# PIC18F45K22 register map
Vendor: Microchip
Registers are 8-bit, read-write, no defined reset value unless marked. A register's access mark holds for its fields unless they carry their own. Addresses are absolute, and some are shared; only a register's first bit layout is shown; [hi:lo] are bit positions; <NAME> marks a mode.

## CONFIG — Configuration words, addresses in ProgramSpace
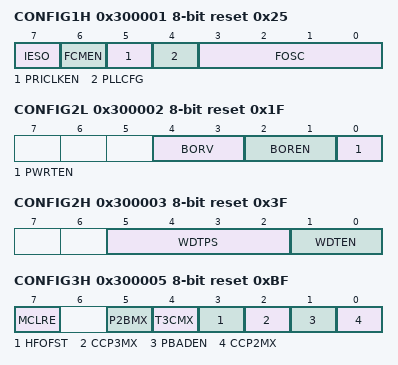
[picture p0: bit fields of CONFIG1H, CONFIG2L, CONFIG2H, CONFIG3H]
0x300001 CONFIG1H reset 0x25
  [7] IESO — Internal/External Oscillator Switchover bit
    0=OFF (Oscillator Switchover mode disabled); 1=ON (Oscillator Switchover mode enabled)
  [6] FCMEN — Fail-Safe Clock Monitor Enable bit
    0=OFF (Fail-Safe Clock Monitor disabled); 1=ON (Fail-Safe Clock Monitor enabled)
  [5] PRICLKEN — Primary clock enable bit
    0=OFF (Primary clock can be disabled by software); 1=ON (Primary clock is always enabled)
  [4] PLLCFG — 4X PLL Enable
    0=OFF (Oscillator used directly); 1=ON (Oscillator multiplied by 4)
  [3:0] FOSC — Oscillator Selection bits
    0b111x=RC (111X External RC oscillator, CLKOUT function on RA6); 13=ECLPIO6 (EC oscillator (low power, <500 kHz)); 12=ECLP (EC oscillator, CLKOUT function on OSC2 (low power, <500 kHz)); 11=ECMPIO6 (EC oscillator (medium power, 500 kHz-16 MHz)); 10=ECMP (EC oscillator, CLKOUT function on OSC2 (medium power, 500 kHz-16 MHz)); 9=INTIO7 (Internal oscillator block, CLKOUT function on OSC2); 8=INTIO67 (Internal oscillator block); 7=RCIO6 (External RC oscillator); 6=RC (External RC oscillator, CLKOUT function on OSC2); 5=ECHPIO6 (EC oscillator (high power, >16 MHz)); 4=ECHP (EC oscillator, CLKOUT function on OSC2 (high power, >16 MHz)); 3=HSMP (HS oscillator (medium power 4-16 MHz)); 2=HSHP (HS oscillator (high power > 16 MHz)); 1=XT (XT oscillator); 0=LP (LP oscillator)
0x300002 CONFIG2L reset 0x1F
  [4:3] BORV — Brown Out Reset Voltage bits
    3=VBOR set to 1.90 V nominal; 2=VBOR set to 2.20 V nominal; 1=VBOR set to 2.50 V nominal; 0=VBOR set to 2.85 V nominal
  [2:1] BOREN — Brown-out Reset Enable bits
    3=SBORDIS (Brown-out Reset enabled in hardware only (SBOREN is disabled)); 2=NOSLP (Brown-out Reset enabled in hardware only and disabled in Sleep mode (SBOREN is disabled)); 1=ON (Brown-out Reset enabled and controlled by software (SBOREN is enabled)); 0=OFF (Brown-out Reset disabled in hardware and software)
  [0] PWRTEN — Power-up Timer Enable bit
    1=OFF (Power up timer disabled); 0=ON (Power up timer enabled)
0x300003 CONFIG2H reset 0x3F
  [5:2] WDTPS — Watchdog Timer Postscale Select bits
    15=1:32768; 14=1:16384; 13=1:8192; 12=1:4096; 11=1:2048; 10=1:1024; 9=1:512; 8=1:256; 7=1:128; 6=1:64; 5=1:32; 4=1:16; 3=1:8; 2=1:4; 1=1:2; 0=1:1
  [1:0] WDTEN — Watchdog Timer Enable bits
    3=ON (WDT is always enabled. SWDTEN bit has no effect); 2=SWON (WDT is controlled by SWDTEN bit of the WDTCON register); 1=NOSLP (WDT is disabled in sleep, otherwise enabled. SWDTEN bit has no effect); 0=OFF (Watch dog timer is always disabled. SWDTEN has no effect.)
0x300005 CONFIG3H reset 0xBF
  [7] MCLRE — MCLR Pin Enable bit
    1=EXTMCLR (MCLR pin enabled, RE3 input pin disabled); 0=INTMCLR (RE3 input pin enabled; MCLR disabled)
  [5] P2BMX — ECCP2 B output mux bit
    1=PORTD2 (P2B is on RD2); 0=PORTC0 (P2B is on RC0)
  [4] T3CMX — Timer3 Clock input mux bit
    1=PORTC0 (T3CKI is on RC0); 0=PORTB5 (T3CKI is on RB5)
  [3] HFOFST — HFINTOSC Fast Start-up
    1=ON (HFINTOSC output and ready status are not delayed by the oscillator stable status); 0=OFF (HFINTOSC output and ready status are delayed by the oscillator stable status)
  [2] CCP3MX — P3A/CCP3 Mux bit
    1=PORTB5 (P3A/CCP3 input/output is multiplexed with RB5); 0=PORTE0 (P3A/CCP3 input/output is mulitplexed with RE0)
  [1] PBADEN — PORTB A/D Enable bit
    1=ON (PORTB<5:0> pins are configured as analog input channels on Reset); 0=OFF (PORTB<5:0> pins are configured as digital I/O on Reset)
  [0] CCP2MX — CCP2 MUX bit
    1=PORTC1 (CCP2 input/output is multiplexed with RC1); 0=PORTB3 (CCP2 input/output is multiplexed with RB3)
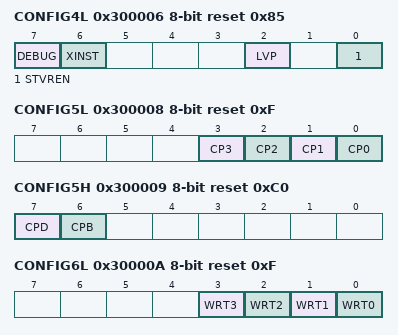
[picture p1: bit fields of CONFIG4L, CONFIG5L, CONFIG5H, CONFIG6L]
0x300006 CONFIG4L reset 0x85
  [7] DEBUG — Background Debug
    1=OFF (Disabled); 0=ON (Enabled)
  [6] XINST — Extended Instruction Set Enable bit
    1=ON (Instruction set extension and Indexed Addressing mode enabled); 0=OFF (Instruction set extension and Indexed Addressing mode disabled (Legacy mode))
  [2] LVP — Single-Supply ICSP Enable bit
    1=ON (Single-Supply ICSP enabled if MCLRE is also 1); 0=OFF (Single-Supply ICSP disabled)
  [0] STVREN — Stack Full/Underflow Reset Enable bit
    1=ON (Stack full/underflow will cause Reset); 0=OFF (Stack full/underflow will not cause Reset)
0x300008 CONFIG5L reset 0xF
  [3] CP3 — Code Protection Block 3
    1=OFF (Block 3 (006000-007FFFh) not code-protected); 0=ON (Block 3 (006000-007FFFh) code-protected)
  [2] CP2 — Code Protection Block 2
    1=OFF (Block 2 (004000-005FFFh) not code-protected); 0=ON (Block 2 (004000-005FFFh) code-protected)
  [1] CP1 — Code Protection Block 1
    1=OFF (Block 1 (002000-003FFFh) not code-protected); 0=ON (Block 1 (002000-003FFFh) code-protected)
  [0] CP0 — Code Protection Block 0
    1=OFF (Block 0 (000800-001FFFh) not code-protected); 0=ON (Block 0 (000800-001FFFh) code-protected)
0x300009 CONFIG5H reset 0xC0
  [7] CPD — Data EEPROM Code Protection bit
    1=OFF (Data EEPROM not code-protected); 0=ON (Data EEPROM code-protected)
  [6] CPB — Boot Block Code Protection bit
    1=OFF (Boot block (000000-0007FFh) not code-protected); 0=ON (Boot block (000000-0007FFh) code-protected)
0x30000A CONFIG6L reset 0xF
  [3] WRT3 — Write Protection Block 3
    1=OFF (Block 3 (006000-007FFFh) not write-protected); 0=ON (Block 3 (006000-007FFFh) write-protected)
  [2] WRT2 — Write Protection Block 2
    1=OFF (Block 2 (004000-005FFFh) not write-protected); 0=ON (Block 2 (004000-005FFFh) write-protected)
  [1] WRT1 — Write Protection Block 1
    1=OFF (Block 1 (002000-003FFFh) not write-protected); 0=ON (Block 1 (002000-003FFFh) write-protected)
  [0] WRT0 — Write Protection Block 0
    1=OFF (Block 0 (000800-001FFFh) not write-protected); 0=ON (Block 0 (000800-001FFFh) write-protected)
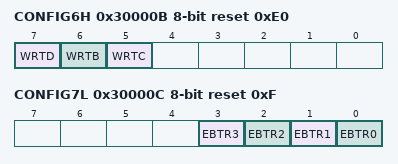
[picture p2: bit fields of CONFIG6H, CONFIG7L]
0x30000B CONFIG6H reset 0xE0
  [7] WRTD — Data EEPROM Write Protection bit
    1=OFF (Data EEPROM not write-protected); 0=ON (Data EEPROM write-protected)
  [6] WRTB — Boot Block Write Protection bit
    1=OFF (Boot Block (000000-0007FFh) not write-protected); 0=ON (Boot Block (000000-0007FFh) write-protected)
  [5] WRTC — Configuration Register Write Protection bit
    1=OFF (Configuration registers (300000-3000FFh) not write-protected); 0=ON (Configuration registers (300000-3000FFh) write-protected)
0x30000C CONFIG7L reset 0xF
  [3] EBTR3 — Table Read Protection Block 3
    1=OFF (Block 3 (006000-007FFFh) not protected from table reads executed in other blocks); 0=ON (Block 3 (006000-007FFFh) protected from table reads executed in other blocks)
  [2] EBTR2 — Table Read Protection Block 2
    1=OFF (Block 2 (004000-005FFFh) not protected from table reads executed in other blocks); 0=ON (Block 2 (004000-005FFFh) protected from table reads executed in other blocks)
  [1] EBTR1 — Table Read Protection Block 1
    1=OFF (Block 1 (002000-003FFFh) not protected from table reads executed in other blocks); 0=ON (Block 1 (002000-003FFFh) protected from table reads executed in other blocks)
  [0] EBTR0 — Table Read Protection Block 0
    1=OFF (Block 0 (000800-001FFFh) not protected from table reads executed in other blocks); 0=ON (Block 0 (000800-001FFFh) protected from table reads executed in other blocks)
0x30000D CONFIG7H reset 0x40
  [6] EBTRB — Boot Block Table Read Protection bit
    1=OFF (Boot Block (000000-0007FFh) not protected from table reads executed in other blocks); 0=ON (Boot Block (000000-0007FFh) protected from table reads executed in other blocks)
